# RFM9x register map
Vendor: Hoperf; Series: RFM9x; File version: 1.0
Hoperf RFM95/96/97/98
Registers are 8-bit, read-write, reset 0x0 unless marked. A register's access mark holds for its fields unless they carry their own. Offsets are from the block's base; lines under a group give offsets from that group; [hi:lo] are bit positions; {n}, {i} and the like mark numbered series; 'fields as' and 'values as' point back to an identical list; <NAME> marks a mode.

## Memory map
0x00000000 LORA size 0x64 — LoRa (TM) mode
0x00000000 FSM_OSK size 0x64 — Device is put in FSM/OSK mode

## Interrupts
118 ADC0_INTREQ_0 (LORA)
119 ADC0_INTREQ_1 (LORA)

## LORA — LoRa (TM) mode
Base 0x00000000; register names take the prefix LORA_
Same registers: FSM_OSK 0x00000000
0x00 FIFO — FIFO read/write access
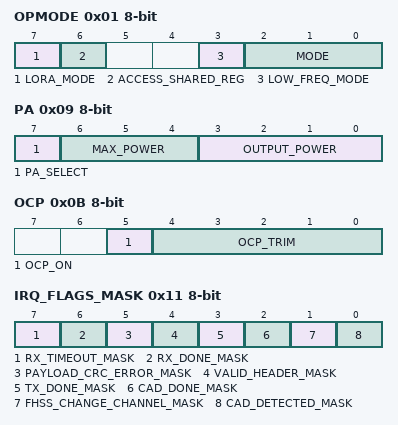
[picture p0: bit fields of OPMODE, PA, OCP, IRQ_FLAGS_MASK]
0x01 OPMODE — Operating mode and LoRa(TM) / FSK selection
  [7] LORA_MODE — Select whether the device should be in long range mode or FSK/OOK mode
    0=FSK_OOK (FSK/OOK mode); 1=LORA (LoRa mode)
  [6] ACCESS_SHARED_REG — Allows to access FSK registers
    0=LORA (Access LoRa registers page); 1=FSK (Access FSK registers)
  [3] LOW_FREQ_MODE — Access low frequency mode registers
    0=HF_MODE (High frequency mode (access to HF test registers)); 1=LF_MODE (Low frequency mode (access to LF test registers))
  [2:0] MODE — Transceiver modes
    0=SLEEP (Sleep mode); 1=STDBY (Standby); 2=FSTX (Fs mode TX); 3=TX (Transmitter mode TX); 4=FSRX (Frequency synthesis RX); 5=RXCONTINOUS (Receive continuous); 6=RXSINGLE (Receive single); 7=CAD (Channel activity detection)
0x06 RF_FREQ_MSB — MSB of the RF carrier frequency
0x07 RF_FREQ_MID — MID of the RF carrier frequency
0x08 RF_FREQ_LSB — LSB of the RF carrier frequency
0x09 PA — PA output pin, max output power, output power
  [7] PA_SELECT — Select PA output pin
    0=RFO (RFO pin. Output limited to 14dBm); 1=PA_BOOST (PA boost pin. Output power limited to 20dBm)
  [6:4] MAX_POWER — Pmax=10.8 + 0.6 * MaxPower (dBm)
  [3:0] OUTPUT_POWER
0x0A PA_RAMP 4-bit — Rise/Fall time of ramp up/down in FSK
  [3:0] PA_RAMP
    0=3_4MS; 1=2MS; 2=1MS; 3=500US; 4=250US; 5=125US; 6=100US; 7=62US; 8=50US; 9=40US; 10=31US; 11=25US; 12=20US; 13=15US; 14=12US; 15=10US
0x0B OCP — Overload current protection config
  [5] OCP_ON — Enables overload current protection
  [4:0] OCP_TRIM — Trimming of OCP current
0x0C LNA — LNA gain and current adjustment
  [6:5] LNA_GAIN — LNA Gain setting
    1=G1 (G1 / Maximum gain); {v}=G{v} (v=2..6)
  [5:4] BOOST_LF — Low frequency (RFI_LF) LNA current adjustment
    0=Default LNA current
  [1:0] BOOST_HF — High frequency (RFI_HF) LNA current adjustment
    0=Default LNA current; 1=BOOST (Boost on)
0x0D FIFO_ADD_PTR — SPI interface address pointer in FIFO data buffer
0x0E FIFO_TX_BASE_ADDR — Write base addres sin FIFO data buffer for TX modulator
0x0F FIFO_RX_BASE_ADDR — Read base address in FIFO data buffer for RX demodulator
0x10 FIFO_RX_CURRENT_ADDR — Start address (in data buffer) of last packet received
0x11 IRQ_FLAGS_MASK — Interrupt flags masks
  [7] RX_TIMEOUT_MASK — Timeout interrupt mask. Setting this bit masks the corresponding IRQ in RegIrqFlags
  [6] RX_DONE_MASK — Packet reception complete interrupt mask. Setting this bit masks the corresponding IRQ in RegIrqFlags
  [5] PAYLOAD_CRC_ERROR_MASK — Payload CRC error interrupt mask. Setting this bit masks the corresponding IRQ in RegIrqFlags
  [4] VALID_HEADER_MASK — Valid header received in Rx mask. Setting this bit masks the corresponding IRQ in RegIrqFlags
  [3] TX_DONE_MASK — FIFO Payload transmission complete interrupt mask. Setting this bit masks the corresponding IRQ in RegIrqFlags
  [2] CAD_DONE_MASK — CAD complete interrupt mask. Setting this bit masks the corresponding IRQ in RegIrqFlags
  [1] FHSS_CHANGE_CHANNEL_MASK — FHSS change channel interrupt mask. Setting this bit masks the corresponding IRQ in RegIrqFlags
  [0] CAD_DETECTED_MASK — Card detected interrupt mask. Setting this masks the corresponding IRQ in RegIrqFlags
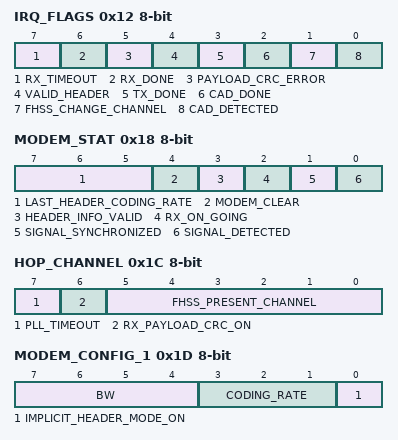
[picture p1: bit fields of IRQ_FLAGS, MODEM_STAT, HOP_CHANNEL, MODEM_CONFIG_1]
0x12 IRQ_FLAGS
  [7] RX_TIMEOUT — Timeout interrupt - a write operation IRQ
  [6] RX_DONE — Packet reception complete interrupt - a write operation clears IRQ
  [5] PAYLOAD_CRC_ERROR — Payload CRC error interrupt - a write operation clears IRQ
  [4] VALID_HEADER — Valid header received in Rx - a write operation clears IRQ
  [3] TX_DONE — FIFO Payload transmission complete interrupt - a write operation clears IRQ
  [2] CAD_DONE — CAD complete - a write operation clears IRQ
  [1] FHSS_CHANGE_CHANNEL — FHSS change channel interrupt - a write operation clears IRQ
  [0] CAD_DETECTED — Valid Lora signal detected during CAD operation - a write operation clears IRQ
0x13 RX_NB_BYTES — Number of payload bytes of latest packet received
0x14 RX_HEADER_COUNT_VALUE_MSB ro — Number of valid headers received since last transition into Rx mode, MSB (15:8). Header and packet counters are reset in Sleep mode
0x15 RX_HEADER_COUNT_VALUE_LSB ro — Number of valid headers received since last transition into Rx mode, LSB (7:0). Header and packet counters are reset in Sleep mode
0x16 RX_PACKET_COUNT_VALUE_MSB ro — Number of valid packets received since last transition into Rx mode, MSB (15:8). Header and packet counters are reset in Sleep mode
0x17 RX_PACKET_COUNT_VALUE_LSB ro — Number of valid packets received since last transition into Rx mode, LSB (7:0). Header and packet counters are reset in Sleep mode
0x18 MODEM_STAT ro — Modem stats
  [7:5] LAST_HEADER_CODING_RATE — Coding rate of last header
  [4] MODEM_CLEAR — Model clear
  [3] HEADER_INFO_VALID
  [2] RX_ON_GOING
  [1] SIGNAL_SYNCHRONIZED
  [0] SIGNAL_DETECTED
0x19 PACKET_SNR ro — Estimation of SNR on last packet received. In two's compliment format multiplied by 4
0x1A PACKET_RSSI ro — RSSI of the latest packet received (dBm)
0x1B RSSI ro — Current RSSI value (dBm)
0x1C HOP_CHANNEL ro — Current value of frequency hopping channel, CRC info and PLL lock info
  [7] PLL_TIMEOUT — Whether PLL failed to lock while attempting a TX/RX/CAD operation
    0=PLL_DID_LOCK; 1=PLL_DID_NOT_LOCK
  [6] RX_PAYLOAD_CRC_ON — CRC information extracted from the received packet header
    0=CRC_OFF (Header indicates CRC off); 1=CRC_ON (Header indicates CRC on)
  [5:0] FHSS_PRESENT_CHANNEL — Current value of frequency hopping channel in use
0x1D MODEM_CONFIG_1 — Modem configuration register 1
  [7:4] BW — Signal bandwith
    0=7_8KHZ; 1=10_4KHZ; 2=15_6KHZ; 3=20_8KHZ; 4=31_25KHZ; 5=41_7KHZ; 6=62_5KHZ; 7=125KHZ; 8=250KHZ; 9=500KHZ
  [3:1] CODING_RATE — Error coding rate
    {v}=4_{v+4} (v=1..4)
  [0] IMPLICIT_HEADER_MODE_ON — Implicit/explicit header mode on
    0=IMPLICIT_MODE (Implicit header mode); 1=EXPLICIT_MODE (Explicit header mode)
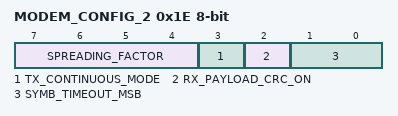
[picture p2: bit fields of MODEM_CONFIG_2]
0x1E MODEM_CONFIG_2 — Modem configuration register 2
  [7:4] SPREADING_FACTOR — Spreading factor (SF) rate (expressed as a base-2 logarithm)
    6=64 chips / symbol; 7=128 chips / symbol; 8=256 chips / symbol; 9=512 chips / symbol; 10=1024 chips / symbol; 11=2048 chips / symbol; 12=4096 chips / symbol
  [3] TX_CONTINUOUS_MODE — Whether Tx is in continuous mode or single packet mode
    0=NORMAL (Single packet); 1=CONTINUOUS_MODE (Send multiple packets across the FIFO (used for spectral analysis))
  [2] RX_PAYLOAD_CRC_ON — CRC information extracted from the received packet header
    values as HOP_CHANNEL.RX_PAYLOAD_CRC_ON
  [1:0] SYMB_TIMEOUT_MSB — RX timeout MSB
0x1F RX_SYMB_TIMEOUT_LSB — RX Symbol timeout LSB. RX operation time-out value expressed as number of symbols
0x20 PREAMBLE_LENGTH_MSB — Preamble length MSB = Preamble Length + 4.25 symbols
0x21 PREAMBLE_LENGTH_LSB — Preamble length LSB = Preamble Length + 4.25 symbols
0x22 PAYLOAD_LENGTH — Payload length in bytes. The register needs to be set in implicit header for the expected packet length. A 0 value is not permitted
0x23 MAX_PAYLOAD_LENGTH — Max payload length in bytes. If header payload length exceeds value a header CRC error is generated. Allows filtering of packet with a bad size.
0x24 FREQ_HOP_PERIOD — Symbol period between frequency hops. 0 = disabled. 1st hop always happen after 1st header symbol
0x25 FIFO_RX_BYTE_ADDR_PTR ro — Current value of RX databuffer pointer (address of last byte written by Lora receiver)
0x26 MODEM_CONFIG_3 — Configure LNA gain setter and static/mobile node
  [3] MOBILE_NODE — Mobile node static or mobile
    0=STATIC_NODE; 1=MOBILE_NODE
  [3:2] LNA_GAIN_SETTER — LNA gain set by regiter or internal AGC loop
    0=REGISTER_LNA_GAIN (LNA gain set by register LnaGain); 1=AGC_LOOP (LNA gain set by the internal AGC loop)

## Licence text in the file
============================================================================ PathfinderZA Software Support ============================================================================ Copyright (c) 2020 PathfinderZA Software (PTY) LTD, . Licensed under the Apache License, Version 2.0 (the "License"); you may not use this file except in compliance with the License. You may obtain a copy of the Licence at http://www.apache.org/licenses/LICENSE-2.0 . Unless required by applicable law or agreed to in writing, software distributed under the License is distributed on an "AS IS" BASIS, WITHOUT WARRANTIES OR CONDITIONS OF ANY KIND, either express or implied. See the License for the specific language governing permissions and limitations under the License. ============================================================================
